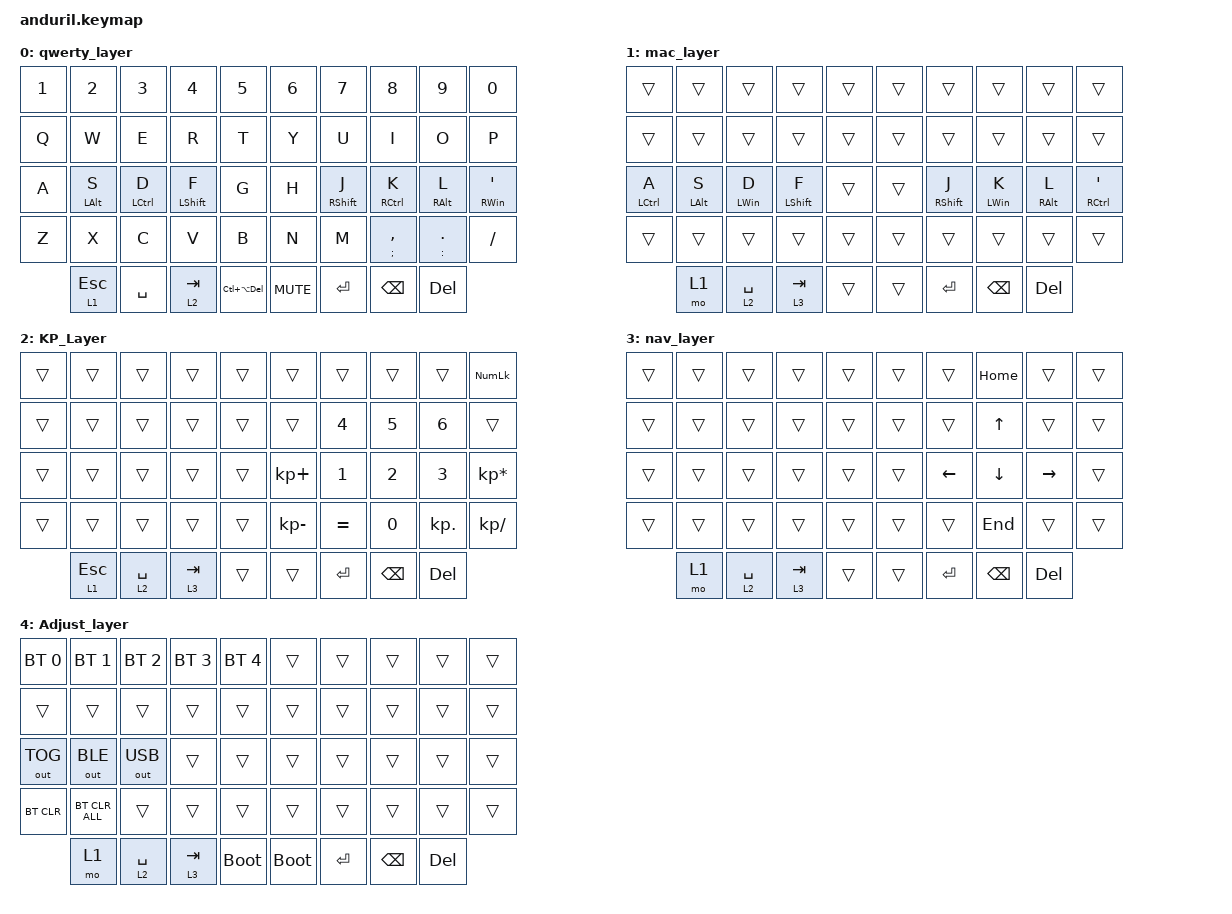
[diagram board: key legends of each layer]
/*
 * Copyright (c) 2020 The ZMK Contributors
 *
 * SPDX-License-Identifier: MIT
 */

#include <behaviors.dtsi>
#include <dt-bindings/zmk/bt.h>
#include <dt-bindings/zmk/keys.h>
#include <dt-bindings/zmk/outputs.h>

#define BASE    0
#define MAC     1
#define LOWER   2
#define RAISE   3
#define ADJUST  4

/ {
    // Activate ADJUST layer by pressing raise and lower

    conditional_layers {
        compatible = "zmk,conditional-layers";

        adjust_layer {
            if-layers = <1>;
            then-layer = <2>;
        };
    };

    combos {
        compatible = "zmk,combos";

        tilde {
            bindings = <&kp GRAVE>;
            key-positions = <0 1>;
        };
    };

    keymap {
        compatible = "zmk,keymap";

        qwerty_layer {
            // ------------------------------------------------------------------------------------------------------------
            // |  1  |  2  |  3   |  4   |  5   |                   |  6   |  7    |  8    |  9   |   0   |
            // |  Q  |  W  |  E   |  R   |  T   |                   |  Y   |  U    |  I    |  O   |   P   |
            // |  A  |  S  |  D   |  F   |  G   |                   |  H   |  J    |  K    |  L   |   ;   |
            // |  Z  |  X  |  C   |  V   |  B   | C/A/D|    | MUTE  |  N   |  M    |  ,    |  .   |   /   |
            //                    | ESC  | SPACE| TAB  |    | ENTER |  BS  |  DEL  | 

            bindings = <
&kp N1        &kp N2          &kp N3       &kp N4       &kp N5           &kp N6      &kp N7        &kp N8          &kp N9         &kp N0
&kp Q         &kp W           &kp E        &kp R        &kp T            &kp Y       &kp U         &kp I           &kp O          &kp P
&kp A         &mt LEFT_ALT S  &mt LCTRL D   &mt LSHFT F  &kp G            &kp H       &mt RSHIFT J  &mt RCTRL  K     &mt RALT L     &mt RWIN SQT
&kp Z         &kp X           &kp C        &kp V        &kp B            &kp N       &kp M         &mt SEMI COMMA  &mt COLON DOT  &kp FSLH
              &lt 1 ESC       &kp SPACE    &lt 2 TAB    &kp LC(LA(DEL))  &kp C_MUTE  &kp ENTER     &kp BSPC        &kp DEL
            >;

            sensor-bindings = <&inc_dec_kp PG_UP PG_DN &inc_dec_kp C_VOL_UP C_VOL_DN>;
        };

        mac_layer {
            // ------------------------------------------------------------------------------------------------------------
            // |  1  |  2  |  3   |  4   |  5   |                   |  6   |  7    |  8    |  9   |   0   |
            // |  Q  |  W  |  E   |  R   |  T   |                   |  Y   |  U    |  I    |  O   |   P   |
            // |  A  |  S  |  D   |  F   |  G   |                   |  H   |  J    |  K    |  L   |   ;   |
            // |  Z  |  X  |  C   |  V   |  B   | C/A/D|    | MUTE  |  N   |  M    |  ,    |  .   |   /   |
            //                    | ESC  | SPACE| TAB  |    | ENTER |  BS  |  DEL  | 

            bindings = <
&trans        &trans          &trans       &trans       &trans  &trans  &trans        &trans       &trans      &trans
&trans        &trans          &trans       &trans       &trans  &trans  &trans        &trans       &trans      &trans
&mt LCTRL A   &mt LEFT_ALT S  &mt LWIN D   &mt LSHFT F  &trans  &trans  &mt RSHIFT J  &mt LWIN  K  &mt RALT L  &mt RCTRL SQT
&trans        &trans          &trans       &trans       &trans  &trans  &trans        &trans       &trans      &trans
              &mo 1           &lt 2 SPACE  &lt 3 TAB    &trans  &trans  &kp ENTER     &kp BSPC     &kp DEL 1
            >;

            sensor-bindings = <&inc_dec_kp PG_UP PG_DN &inc_dec_kp C_VOL_UP C_VOL_DN>;
        };
        KP_Layer {
            // ------------------------------------------------------------------------------------------------------------
            // |  1  |  2  |  3   |  4   |  5   |                   |  6   |  7    |  8    |  9   |   0   |
            // |  Q  |  W  |  E   |  R   |  T   |                   |  Y   |  U    |  I    |  O   |   P   |
            // |  A  |  S  |  D   |  F   |  G   |                   |  H   |  J    |  K    |  L   |   ;   |
            // |  Z  |  X  |  C   |  V   |  B   | C/A/D|    | MUTE  |  N   |  M    |  ,    |  .   |   /   |
            //                    | ESC  | SPACE| TAB  |    | ENTER |  BS  |  DEL  | 

            bindings = <
&trans  &trans        &trans       &trans     &trans  &trans        &trans     &trans    &trans      &kp KP_NUM
&trans  &trans        &trans       &trans     &trans  &trans        &kp N4     &kp N5    &kp N6      &trans
&trans  &trans        &trans       &trans     &trans  &kp KP_PLUS   &kp N1     &kp N2    &kp N3      &kp KP_ASTERISK
&trans  &trans        &trans       &trans     &trans  &kp KP_MINUS  &kp EQUAL  &kp N0    &kp KP_DOT  &kp KP_DIVIDE
        &lt 1 ESCAPE  &lt 2 SPACE  &lt 3 TAB  &trans  &trans        &kp ENTER  &kp BSPC  &kp DEL
            >;

            sensor-bindings = <&inc_dec_kp PG_UP PG_DN &inc_dec_kp C_VOL_UP C_VOL_DN>;
        };

        nav_layer {
            // ------------------------------------------------------------------------------------------------------------
            // |  1  |  2  |  3   |  4   |  5   |                   |  6   |  7    |  8    |  9   |   0   |
            // |  Q  |  W  |  E   |  R   |  T   |                   |  Y   |  U    |  I    |  O   |   P   |
            // |  A  |  S  |  D   |  F   |  G   |                   |  H   |  J    |  K    |  L   |   ;   |
            // |  Z  |  X  |  C   |  V   |  B   | C/A/D|    | MUTE  |  N   |  M    |  ,    |  .   |   /   |
            //                    | ESC  | SPACE| TAB  |    | ENTER |  BS  |  DEL  | 

            bindings = <
&trans  &trans  &trans       &trans     &trans  &trans  &trans     &kp HOME  &trans     &trans
&trans  &trans  &trans       &trans     &trans  &trans  &trans     &kp UP    &trans     &trans
&trans  &trans  &trans       &trans     &trans  &trans  &kp LEFT   &kp DOWN  &kp RIGHT  &trans
&trans  &trans  &trans       &trans     &trans  &trans  &trans     &kp END   &trans     &trans
        &mo 1   &lt 2 SPACE  &lt 3 TAB  &trans  &trans  &kp ENTER  &kp BSPC  &kp DEL 1
            >;

            sensor-bindings = <&inc_dec_kp PG_UP PG_DN &inc_dec_kp C_VOL_UP C_VOL_DN>;
        };

        Adjust_layer {
            // ------------------------------------------------------------------------------------------------------------
            // |  1  |  2  |  3   |  4   |  5   |                   |  6   |  7    |  8    |  9   |   0   |
            // |  Q  |  W  |  E   |  R   |  T   |                   |  Y   |  U    |  I    |  O   |   P   |
            // |  A  |  S  |  D   |  F   |  G   |                   |  H   |  J    |  K    |  L   |   ;   |
            // |  Z  |  X  |  C   |  V   |  B   | C/A/D|    | MUTE  |  N   |  M    |  ,    |  .   |   /   |
            //                    | ESC  | SPACE| TAB  |    | ENTER |  BS  |  DEL  | 

            bindings = <
&bt BT_SEL 0  &bt BT_SEL 1    &bt BT_SEL 2  &bt BT_SEL 3  &bt BT_SEL 4  &trans       &trans     &trans    &trans   &trans
&trans        &trans          &trans        &trans        &trans        &trans       &trans     &trans    &trans   &trans
&out OUT_TOG  &out OUT_BLE    &out OUT_USB  &trans        &trans        &trans       &trans     &trans    &trans   &trans
&bt BT_CLR    &bt BT_CLR_ALL  &trans        &trans        &trans        &trans       &trans     &trans    &trans   &trans
              &mo 1           &lt 2 SPACE   &lt 3 TAB     &bootloader   &bootloader  &kp ENTER  &kp BSPC  &kp DEL
            >;

            sensor-bindings = <&inc_dec_kp PG_UP PG_DN &inc_dec_kp C_VOL_UP C_VOL_DN>;
        };
    };
};
